# neorv32 register map
Vendor: github.com/stnolting/neorv32; Series: RISC-V; File version: 1.12.8
CPU: other r1p0, little endian, MPU, FPU, I-cache, D-cache, ITCM, DTCM, 4 interrupt priority bits
Address unit: 16 bits
Registers are 32-bit, read-write, reset 0x0 unless marked. A register's access mark holds for its fields unless they carry their own. Offsets are from the block's base; [hi:lo] are bit positions; lines under a group give offsets from that group; {n}, {i} and the like mark numbered series.

## PWM — Pulse-width modulation controller
Base 0xFFF00000
0x00 ENABLE — Channel enable
0x04 POLARITY — Channel polarity
0x08 CLKPRSC — Clock prescaler select
0x0C MODE — Channel operation mode (0 = fast-PWM; 1 = phase-correct PWM)
{0x80+4i} CHANNEL[{i}] (i=0..31) group — Channel configuration register
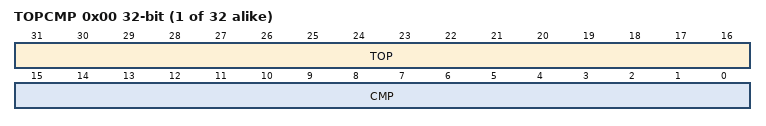
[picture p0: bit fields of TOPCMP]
  0x00 TOPCMP — Channel counter full word access alias
    [31:16] TOP — Channel counter top/wrap value
    [15:0] CMP — Channel counter compare value

## GPTMR — General purpose timer
Base 0xFFF10000
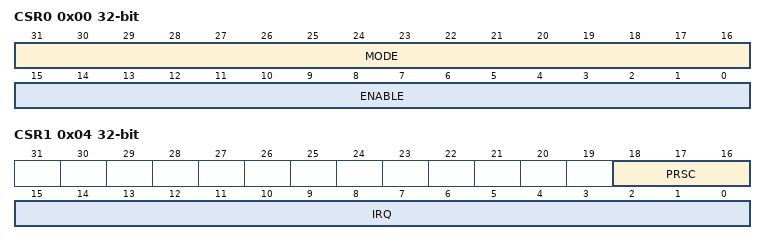
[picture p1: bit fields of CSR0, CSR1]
0x00 CSR0 — Control and status register 0
  [31:16] MODE — Per-slice mode bit (0 = single-shot mode, 1 = continuous mode)
  [15:0] ENABLE — Per-slice enable bit
0x04 CSR1 — Control and status register 1
  [18:16] PRSC — Global clock prescaler select
  [15:0] IRQ — Per-slice interrupt-pending bit; write 0 to clear
{0x80+8i} SLICE[{i}] (i=0..15) group — Timer slice
  0x00 CNT — Counter register
  0x04 THR — Threshold register

## ONEWIRE — 1-Wire Interface Controller
Base 0xFFF20000
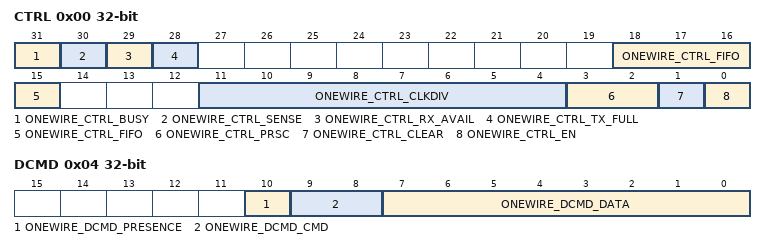
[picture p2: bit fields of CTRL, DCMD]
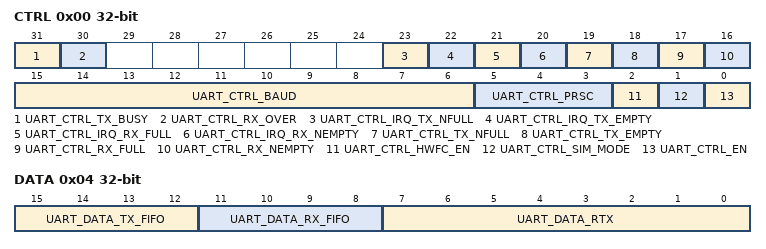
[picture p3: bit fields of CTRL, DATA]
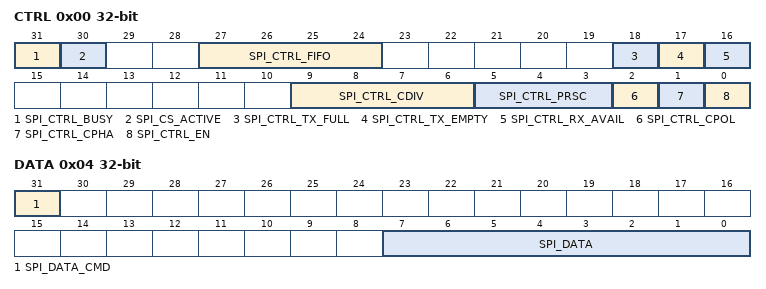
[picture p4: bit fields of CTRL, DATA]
0x00 CTRL — Control register
  [31] ONEWIRE_CTRL_BUSY ro — Operation in progress when set
  [30] ONEWIRE_CTRL_SENSE ro — Current state of the 1-wire bus line
  [29] ONEWIRE_CTRL_RX_AVAIL ro — RX FIFO data available
  [28] ONEWIRE_CTRL_TX_FULL ro — TX FIFO full
  [18:15] ONEWIRE_CTRL_FIFO ro — log2(ONEWIRE FIFO size)
  [11:4] ONEWIRE_CTRL_CLKDIV — Clock divider
  [3:2] ONEWIRE_CTRL_PRSC — Clock prescaler select
  [1] ONEWIRE_CTRL_CLEAR wo — Clear RXT FIFO, auto-clears
  [0] ONEWIRE_CTRL_EN — ONEWIRE controller enable
0x04 DCMD read-modifies — Read/write transmission data/command register
  [10] ONEWIRE_DCMD_PRESENCE ro — Bus presence detected
  [9:8] ONEWIRE_DCMD_CMD wo — Operation command
  [7:0] ONEWIRE_DCMD_DATA — RTX data, transmitted LSB-first

## CLINT — Core local interruptor
Base 0xFFF40000
0x00 MSWI0 — Machine software interrupt; hart 0
0x4000 MTIMECMP0_LOW — Machine timer compare low word; hart0
0x4004 MTIMECMP0_HI — Machine timer compare low word; hart0
0xBFF8 MTIME_LOW — Machine timer low word
0xBFFC MTIME_HI — Machine timer high word

## UART0 — Primary universal asynchronous receiver and transmitter
Base 0xFFF50000
Same registers: UART1 0xFFF60000
0x00 CTRL — Control register
  [31] UART_CTRL_TX_BUSY ro — Transmitter busy or TX FIFO not empty
  [30] UART_CTRL_RX_OVER ro — RX FIFO overflow
  [23] UART_CTRL_IRQ_TX_NFULL — Fire IRQ if TX FIFO not full
  [22] UART_CTRL_IRQ_TX_EMPTY — Fire IRQ if TX FIFO empty
  [21] UART_CTRL_IRQ_RX_FULL — Fire IRQ if RX FIFO full
  [20] UART_CTRL_IRQ_RX_NEMPTY — Fire IRQ if RX FIFO not empty
  [19] UART_CTRL_TX_NFULL ro — TX FIFO not full
  [18] UART_CTRL_TX_EMPTY ro — TX FIFO empty
  [17] UART_CTRL_RX_FULL ro — RX FIFO full
  [16] UART_CTRL_RX_NEMPTY ro — RX FIFO not empty
  [15:6] UART_CTRL_BAUD — BAUD rate divisor
  [5:3] UART_CTRL_PRSC — CLock prescaler select
  [2] UART_CTRL_HWFC_EN — Enable RTS/CTS hardware flow-control
  [1] UART_CTRL_SIM_MODE — Simulation output override enable, for use in simulation only
  [0] UART_CTRL_EN — UART enable flag
0x04 DATA read-modifies — RTX data register
  [15:12] UART_DATA_TX_FIFO ro — log2(TX FIFO size)
  [11:8] UART_DATA_RX_FIFO ro — log2(RX FIFO size)
  [7:0] UART_DATA_RTX — Receive/transmit data

## SPI — Serial peripheral interface controller
Base 0xFFF80000
0x00 CTRL — Control register
  [31] SPI_CTRL_BUSY ro — SPI busy flag (transmission in progress and TX FIFO not empty)
  [30] SPI_CS_ACTIVE ro — Set if a chip-select line is active
  [27:24] SPI_CTRL_FIFO ro — log2(FIFO size)
  [18] SPI_CTRL_TX_FULL ro — TX FIFO is full
  [17] SPI_CTRL_TX_EMPTY ro — TX FIFO is empty
  [16] SPI_CTRL_RX_AVAIL ro — RX FIFO data available (RX FIFO not empty)
  [9:6] SPI_CTRL_CDIV — SPI clock divider
  [5:3] SPI_CTRL_PRSC — Clock prescaler select
  [2] SPI_CTRL_CPOL — Clock polarity
  [1] SPI_CTRL_CPHA — Clock phase
  [0] SPI_CTRL_EN — SPI enable flag
0x04 DATA read-modifies
  [31] SPI_DATA_CMD wo — SPI TX data (0) / command (1) select
  [7:0] SPI_DATA — RX data / TX data/command (via FIFOs)
